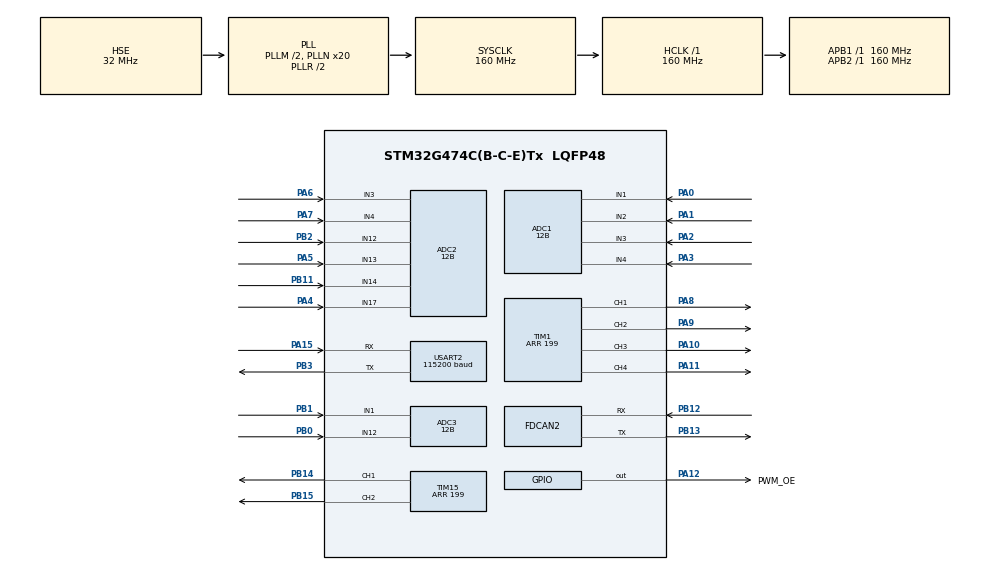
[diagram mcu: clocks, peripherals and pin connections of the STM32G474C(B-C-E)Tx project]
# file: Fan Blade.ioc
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ADC1.Channel-0\#ChannelRegularConversion=ADC_CHANNEL_1
ADC1.Channel-1\#ChannelRegularConversion=ADC_CHANNEL_2
ADC1.Channel-2\#ChannelRegularConversion=ADC_CHANNEL_3
ADC1.Channel-3\#ChannelRegularConversion=ADC_CHANNEL_4
ADC1.ClockPrescaler=ADC_CLOCK_SYNC_PCLK_DIV4
ADC1.ContinuousConvMode=DISABLE
ADC1.DMAContinuousRequests=ENABLE
ADC1.DataAlign=ADC_DATAALIGN_RIGHT
ADC1.DiscontinuousConvMode=DISABLE
ADC1.EOCSelection=ADC_EOC_SEQ_CONV
ADC1.ExternalTrigConv=ADC_EXTERNALTRIG_T6_TRGO
ADC1.ExternalTrigConvEdge=ADC_EXTERNALTRIGCONVEDGE_RISING
ADC1.LowPowerAutoWait=DISABLE
ADC1.NbrOfConversion=4
ADC1.NbrOfConversionFlag=1
ADC1.OffsetNumber-0\#ChannelRegularConversion=ADC_OFFSET_NONE
ADC1.OffsetNumber-1\#ChannelRegularConversion=ADC_OFFSET_NONE
ADC1.OffsetNumber-2\#ChannelRegularConversion=ADC_OFFSET_NONE
ADC1.OffsetNumber-3\#ChannelRegularConversion=ADC_OFFSET_NONE
ADC1.Overrun=ADC_OVR_DATA_OVERWRITTEN
ADC1.OversamplingMode=DISABLE
ADC1.Rank-0\#ChannelRegularConversion=1
ADC1.Rank-1\#ChannelRegularConversion=2
ADC1.Rank-2\#ChannelRegularConversion=3
ADC1.Rank-3\#ChannelRegularConversion=4
ADC1.Resolution=ADC_RESOLUTION_12B
ADC1.SamplingTime-0\#ChannelRegularConversion=ADC_SAMPLETIME_47CYCLES_5
ADC1.SamplingTime-1\#ChannelRegularConversion=ADC_SAMPLETIME_47CYCLES_5
ADC1.SamplingTime-2\#ChannelRegularConversion=ADC_SAMPLETIME_47CYCLES_5
ADC1.SamplingTime-3\#ChannelRegularConversion=ADC_SAMPLETIME_47CYCLES_5
ADC1.ScanConvMode=ADC_SCAN_ENABLE
ADC1.master=1
ADC2.Channel-0\#ChannelRegularConversion=ADC_CHANNEL_17
ADC2.Channel-1\#ChannelRegularConversion=ADC_CHANNEL_13
ADC2.Channel-2\#ChannelRegularConversion=ADC_CHANNEL_3
ADC2.Channel-3\#ChannelRegularConversion=ADC_CHANNEL_4
ADC2.ClockPrescaler=ADC_CLOCK_SYNC_PCLK_DIV4
ADC2.ContinuousConvMode=DISABLE
ADC2.DMAContinuousRequests=ENABLE
ADC2.DataAlign=ADC_DATAALIGN_RIGHT
ADC2.DiscontinuousConvMode=DISABLE
ADC2.EOCSelection=ADC_EOC_SEQ_CONV
ADC2.ExternalTrigConv=ADC_EXTERNALTRIG_T6_TRGO
ADC2.ExternalTrigConvEdge=ADC_EXTERNALTRIGCONVEDGE_RISING
ADC2.LowPowerAutoWait=DISABLE
ADC2.NbrOfConversion=4
ADC2.NbrOfConversionFlag=1
ADC2.OffsetNumber-0\#ChannelRegularConversion=ADC_OFFSET_NONE
ADC2.OffsetNumber-1\#ChannelRegularConversion=ADC_OFFSET_NONE
ADC2.OffsetNumber-2\#ChannelRegularConversion=ADC_OFFSET_NONE
ADC2.OffsetNumber-3\#ChannelRegularConversion=ADC_OFFSET_NONE
ADC2.Overrun=ADC_OVR_DATA_OVERWRITTEN
ADC2.OversamplingMode=DISABLE
ADC2.Rank-0\#ChannelRegularConversion=1
ADC2.Rank-1\#ChannelRegularConversion=2
ADC2.Rank-2\#ChannelRegularConversion=3
ADC2.Rank-3\#ChannelRegularConversion=4
ADC2.Resolution=ADC_RESOLUTION_12B
ADC2.SamplingTime-0\#ChannelRegularConversion=ADC_SAMPLETIME_47CYCLES_5
ADC2.SamplingTime-1\#ChannelRegularConversion=ADC_SAMPLETIME_47CYCLES_5
ADC2.SamplingTime-2\#ChannelRegularConversion=ADC_SAMPLETIME_47CYCLES_5
ADC2.SamplingTime-3\#ChannelRegularConversion=ADC_SAMPLETIME_47CYCLES_5
ADC2.ScanConvMode=ADC_SCAN_ENABLE
ADC3.Channel-0\#ChannelRegularConversion=ADC_CHANNEL_12
ADC3.Channel-1\#ChannelRegularConversion=ADC_CHANNEL_1
ADC3.ClockPrescaler=ADC_CLOCK_SYNC_PCLK_DIV4
ADC3.ContinuousConvMode=DISABLE
ADC3.DMAContinuousRequests=ENABLE
ADC3.DataAlign=ADC_DATAALIGN_RIGHT
ADC3.DiscontinuousConvMode=DISABLE
ADC3.EOCSelection=ADC_EOC_SEQ_CONV
ADC3.ExternalTrigConv=ADC_EXTERNALTRIG_T6_TRGO
ADC3.ExternalTrigConvEdge=ADC_EXTERNALTRIGCONVEDGE_RISING
ADC3.LowPowerAutoWait=DISABLE
ADC3.NbrOfConversion=2
ADC3.NbrOfConversionFlag=1
ADC3.OffsetNumber-0\#ChannelRegularConversion=ADC_OFFSET_NONE
ADC3.OffsetNumber-1\#ChannelRegularConversion=ADC_OFFSET_NONE
ADC3.Overrun=ADC_OVR_DATA_OVERWRITTEN
ADC3.OversamplingMode=DISABLE
ADC3.Rank-0\#ChannelRegularConversion=1
ADC3.Rank-1\#ChannelRegularConversion=2
ADC3.Resolution=ADC_RESOLUTION_12B
ADC3.SamplingTime-0\#ChannelRegularConversion=ADC_SAMPLETIME_47CYCLES_5
ADC3.SamplingTime-1\#ChannelRegularConversion=ADC_SAMPLETIME_47CYCLES_5
ADC3.ScanConvMode=ADC_SCAN_ENABLE
ADC3.master=1
Dma.ADC1.0.Direction=DMA_PERIPH_TO_MEMORY
Dma.ADC1.0.EventEnable=DISABLE
Dma.ADC1.0.Instance=DMA1_Channel1
Dma.ADC1.0.MemDataAlignment=DMA_MDATAALIGN_HALFWORD
Dma.ADC1.0.MemInc=DMA_MINC_ENABLE
Dma.ADC1.0.Mode=DMA_CIRCULAR
Dma.ADC1.0.PeriphDataAlignment=DMA_PDATAALIGN_HALFWORD
Dma.ADC1.0.PeriphInc=DMA_PINC_DISABLE
Dma.ADC1.0.Polarity=HAL_DMAMUX_REQ_GEN_RISING
Dma.ADC1.0.Priority=DMA_PRIORITY_HIGH
Dma.ADC1.0.RequestNumber=1
Dma.ADC1.0.SignalID=NONE
Dma.ADC1.0.SyncEnable=DISABLE
Dma.ADC1.0.SyncPolarity=HAL_DMAMUX_SYNC_NO_EVENT
Dma.ADC1.0.SyncRequestNumber=1
Dma.ADC1.0.SyncSignalID=NONE
Dma.ADC2.1.Direction=DMA_PERIPH_TO_MEMORY
Dma.ADC2.1.EventEnable=DISABLE
Dma.ADC2.1.Instance=DMA1_Channel2
Dma.ADC2.1.MemDataAlignment=DMA_MDATAALIGN_HALFWORD
Dma.ADC2.1.MemInc=DMA_MINC_ENABLE
Dma.ADC2.1.Mode=DMA_CIRCULAR
Dma.ADC2.1.PeriphDataAlignment=DMA_PDATAALIGN_HALFWORD
Dma.ADC2.1.PeriphInc=DMA_PINC_DISABLE
Dma.ADC2.1.Polarity=HAL_DMAMUX_REQ_GEN_RISING
Dma.ADC2.1.Priority=DMA_PRIORITY_HIGH
Dma.ADC2.1.RequestNumber=1
Dma.ADC2.1.SignalID=NONE
Dma.ADC2.1.SyncEnable=DISABLE
Dma.ADC2.1.SyncPolarity=HAL_DMAMUX_SYNC_NO_EVENT
Dma.ADC2.1.SyncRequestNumber=1
Dma.ADC2.1.SyncSignalID=NONE
Dma.ADC3.2.Direction=DMA_PERIPH_TO_MEMORY
Dma.ADC3.2.EventEnable=DISABLE
Dma.ADC3.2.Instance=DMA1_Channel3
Dma.ADC3.2.MemDataAlignment=DMA_MDATAALIGN_HALFWORD
Dma.ADC3.2.MemInc=DMA_MINC_ENABLE
Dma.ADC3.2.Mode=DMA_CIRCULAR
Dma.ADC3.2.PeriphDataAlignment=DMA_PDATAALIGN_HALFWORD
Dma.ADC3.2.PeriphInc=DMA_PINC_DISABLE
Dma.ADC3.2.Polarity=HAL_DMAMUX_REQ_GEN_RISING
Dma.ADC3.2.Priority=DMA_PRIORITY_HIGH
Dma.ADC3.2.RequestNumber=1
Dma.ADC3.2.SignalID=NONE
Dma.ADC3.2.SyncEnable=DISABLE
Dma.ADC3.2.SyncPolarity=HAL_DMAMUX_SYNC_NO_EVENT
Dma.ADC3.2.SyncRequestNumber=1
Dma.ADC3.2.SyncSignalID=NONE
Dma.Request0=ADC1
Dma.Request1=ADC2
Dma.Request2=ADC3
Dma.Request3=USART2_RX
Dma.Request4=USART2_TX
Dma.USART2_RX.3.Direction=DMA_PERIPH_TO_MEMORY
Dma.USART2_RX.3.EventEnable=DISABLE
Dma.USART2_RX.3.Instance=DMA1_Channel4
Dma.USART2_RX.3.MemDataAlignment=DMA_MDATAALIGN_BYTE
Dma.USART2_RX.3.MemInc=DMA_MINC_ENABLE
Dma.USART2_RX.3.Mode=DMA_CIRCULAR
Dma.USART2_RX.3.PeriphDataAlignment=DMA_PDATAALIGN_BYTE
Dma.USART2_RX.3.PeriphInc=DMA_PINC_DISABLE
Dma.USART2_RX.3.Polarity=HAL_DMAMUX_REQ_GEN_RISING
Dma.USART2_RX.3.Priority=DMA_PRIORITY_LOW
Dma.USART2_RX.3.RequestNumber=1
Dma.USART2_RX.3.SignalID=NONE
Dma.USART2_RX.3.SyncEnable=DISABLE
Dma.USART2_RX.3.SyncPolarity=HAL_DMAMUX_SYNC_NO_EVENT
Dma.USART2_RX.3.SyncRequestNumber=1
Dma.USART2_RX.3.SyncSignalID=NONE
Dma.USART2_TX.4.Direction=DMA_MEMORY_TO_PERIPH
Dma.USART2_TX.4.EventEnable=DISABLE
Dma.USART2_TX.4.Instance=DMA1_Channel5
Dma.USART2_TX.4.MemDataAlignment=DMA_MDATAALIGN_BYTE
Dma.USART2_TX.4.MemInc=DMA_MINC_ENABLE
Dma.USART2_TX.4.Mode=DMA_NORMAL
Dma.USART2_TX.4.PeriphDataAlignment=DMA_PDATAALIGN_BYTE
Dma.USART2_TX.4.PeriphInc=DMA_PINC_DISABLE
Dma.USART2_TX.4.Polarity=HAL_DMAMUX_REQ_GEN_RISING
Dma.USART2_TX.4.Priority=DMA_PRIORITY_LOW
Dma.USART2_TX.4.RequestNumber=1
Dma.USART2_TX.4.SignalID=NONE
Dma.USART2_TX.4.SyncEnable=DISABLE
Dma.USART2_TX.4.SyncPolarity=HAL_DMAMUX_SYNC_NO_EVENT
Dma.USART2_TX.4.SyncRequestNumber=1
Dma.USART2_TX.4.SyncSignalID=NONE
FDCAN2.AutoRetransmission=ENABLE
FDCAN2.CalculateBaudRateData=1000000
FDCAN2.CalculateBaudRateNominal=1000000
FDCAN2.CalculateTimeBitData=1000
FDCAN2.CalculateTimeBitNominal=1000
FDCAN2.CalculateTimeQuantumData=50.0
FDCAN2.CalculateTimeQuantumNominal=50.0
FDCAN2.ClockDivider=FDCAN_CLOCK_DIV1
FDCAN2.DataPrescaler=2
FDCAN2.DataSyncJumpWidth=4
FDCAN2.DataTimeSeg1=15
FDCAN2.DataTimeSeg2=4
FDCAN2.ExtFiltersNbr=0
FDCAN2.FrameFormat=FDCAN_FRAME_CLASSIC
FDCAN2.Mode=FDCAN_MODE_NORMAL
FDCAN2.NominalPrescaler=2
FDCAN2.NominalSyncJumpWidth=4
FDCAN2.NominalTimeSeg1=15
FDCAN2.NominalTimeSeg2=4
FDCAN2.ProtocolException=DISABLE
FDCAN2.StdFiltersNbr=2
FDCAN2.TransmitPause=DISABLE
FDCAN2.TxFifoQueueMode=FDCAN_TX_QUEUE_OPERATION
Mcu.Family=STM32G4
Mcu.Name=STM32G474C(B-C-E)Tx
Mcu.Package=LQFP48
NVIC.ADC1_2_IRQn=true\:2\:0\:true\:false\:true\:false\:true\:true
NVIC.ADC3_IRQn=true\:2\:0\:true\:false\:true\:false\:true\:true
NVIC.DMA1_Channel1_IRQn=true\:2\:0\:true\:false\:true\:false\:true\:true
NVIC.DMA1_Channel2_IRQn=true\:2\:0\:true\:false\:true\:false\:true\:true
NVIC.DMA1_Channel3_IRQn=true\:2\:0\:true\:false\:true\:false\:true\:true
NVIC.DMA1_Channel4_IRQn=true\:5\:0\:true\:false\:true\:false\:true\:true
NVIC.DMA1_Channel5_IRQn=true\:5\:0\:true\:false\:true\:false\:true\:true
NVIC.FDCAN2_IT0_IRQn=true\:3\:0\:true\:false\:true\:false\:true\:true
NVIC.PriorityGroup=NVIC_PRIORITYGROUP_4
NVIC.USART2_IRQn=true\:5\:0\:true\:false\:true\:false\:true\:true
PA0.Mode=IN1-Single-Ended
PA0.Signal=ADC1_IN1
PA1.Mode=IN2-Single-Ended
PA1.Signal=ADC1_IN2
PA10.Signal=S_TIM1_CH3
PA11.Signal=S_TIM1_CH4
PA12.GPIO_Label=PWM_OE
PA12.GPIO_ModeDefaultOutputPP=GPIO_MODE_OUTPUT_PP
PA12.GPIO_PuPd=GPIO_NOPULL
PA12.GPIO_Speed=GPIO_SPEED_FREQ_LOW
PA12.PinState=GPIO_PIN_RESET
PA12.Signal=GPIO_Output
PA13.Mode=Serial_Wire
PA13.Signal=SYS_JTMS-SWDIO
PA14.Mode=Serial_Wire
PA14.Signal=SYS_JTCK-SWCLK
PA15.Mode=Asynchronous
PA15.Signal=USART2_RX
PA2.Mode=IN3-Single-Ended
PA2.Signal=ADC1_IN3
PA3.Mode=IN4-Single-Ended
PA3.Signal=ADC1_IN4
PA4.Mode=IN17-Single-Ended
PA4.Signal=ADC2_IN17
PA5.Mode=IN13-Single-Ended
PA5.Signal=ADC2_IN13
PA6.Mode=IN3-Single-Ended
PA6.Signal=ADC2_IN3
PA7.Mode=IN4-Single-Ended
PA7.Signal=ADC2_IN4
PA8.GPIO_PuPd=GPIO_PULLDOWN
PA8.GPIO_Speed=GPIO_SPEED_FREQ_HIGH
PA8.Signal=S_TIM1_CH1
PA9.Signal=S_TIM1_CH2
PB0.Mode=IN12-Single-Ended
PB0.Signal=ADC3_IN12
PB1.Mode=IN1-Single-Ended
PB1.Signal=ADC3_IN1
PB11.Mode=IN14-Single-Ended
PB11.Signal=ADC2_IN14
PB12.Mode=FDCAN_Activate
PB12.Signal=FDCAN2_RX
PB13.Mode=FDCAN_Activate
PB13.Signal=FDCAN2_TX
PB14.Signal=S_TIM15_CH1
PB15.Signal=S_TIM15_CH2
PB2.Mode=IN12-Single-Ended
PB2.Signal=ADC2_IN12
PB3.Mode=Asynchronous
PB3.Signal=USART2_TX
PF0-OSC_IN.Mode=HSE-External-Oscillator
PF0-OSC_IN.Signal=RCC_OSC_IN
PF1-OSC_OUT.Mode=HSE-External-Oscillator
PF1-OSC_OUT.Signal=RCC_OSC_OUT
ProjectManager.HeapSize=0x200
ProjectManager.StackSize=0x1000
ProjectManager.TargetToolchain=CMake
RCC.ADC12CLockSelection=RCC_ADC12CLKSOURCE_SYSCLK
RCC.ADC12Freq_Value=160000000
RCC.ADC345CLockSelection=RCC_ADC345CLKSOURCE_SYSCLK
RCC.ADC345Freq_Value=160000000
RCC.AHBFreq_Value=160000000
RCC.APB1Freq_Value=160000000
RCC.APB1TimFreq_Value=160000000
RCC.APB2Freq_Value=160000000
RCC.APB2TimFreq_Value=160000000
RCC.CK48CLockSelection=RCC_USBCLKSOURCE_HSI48
RCC.CortexFreq_Value=160000000
RCC.EXTERNAL_CLOCK_VALUE=12288000
RCC.FDCANCLockSelection=RCC_FDCANCLKSOURCE_PLL
RCC.HCLKFreq_Value=160000000
RCC.HSE_VALUE=32000000
RCC.HSI48_VALUE=48000000
RCC.HSI_VALUE=16000000
RCC.LSE_VALUE=32768
RCC.PLLM=RCC_PLLM_DIV2
RCC.PLLN=20
RCC.PLLP=RCC_PLLP_DIV2
RCC.PLLQ=RCC_PLLQ_DIV8
RCC.PLLR=RCC_PLLR_DIV2
RCC.PLLSourceVirtual=RCC_PLLSOURCE_HSE
RCC.PWR_Regulator_Voltage_Scale=PWR_REGULATOR_VOLTAGE_SCALE1_BOOST
RCC.SYSCLKFreq_VALUE=160000000
RCC.SYSCLKSource=RCC_SYSCLKSOURCE_PLLCLK
RCC.USART1CLockSelection=RCC_USART1CLKSOURCE_PCLK2
RCC.USART2CLockSelection=RCC_USART2CLKSOURCE_PCLK1
RCC.USBFreq_Value=48000000
RCC.VCOOutputFreq_Value=320000000
SH.S_TIM15_CH1.0=TIM15_CH1,PWM Generation1 CH1
SH.S_TIM15_CH2.0=TIM15_CH2,PWM Generation2 CH2
SH.S_TIM1_CH1.0=TIM1_CH1,PWM Generation1 CH1
SH.S_TIM1_CH2.0=TIM1_CH2,PWM Generation2 CH2
SH.S_TIM1_CH3.0=TIM1_CH3,PWM Generation3 CH3
SH.S_TIM1_CH4.0=TIM1_CH4,PWM Generation4 CH4
TIM1.Channel-PWM\ Generation1\ CH1=TIM_CHANNEL_1
TIM1.Channel-PWM\ Generation2\ CH2=TIM_CHANNEL_2
TIM1.Channel-PWM\ Generation3\ CH3=TIM_CHANNEL_3
TIM1.Channel-PWM\ Generation4\ CH4=TIM_CHANNEL_4
TIM1.PeriodNoDither=199
TIM15.Channel-PWM\ Generation1\ CH1=TIM_CHANNEL_1
TIM15.Channel-PWM\ Generation2\ CH2=TIM_CHANNEL_2
TIM15.PeriodNoDither=199
TIM6.PeriodNoDither=99
TIM6.Prescaler=159
TIM6.TIM_MasterOutputTrigger=TIM_TRGO_UPDATE
USART2.BaudRate=115200
USART2.ClockPrescaler=PRESCALER_DIV1
USART2.FIFOMode=FIFOMODE_DISABLE
USART2.Mode=MODE_TX_RX
USART2.OverSampling=UART_OVERSAMPLING_16
USART2.Parity=PARITY_NONE
USART2.StopBits=STOPBITS_1
USART2.VirtualMode-Asynchronous=VM_ASYNC
USART2.WordLength=WORDLENGTH_8B
VP_SYS_VS_DBSignals.Mode=DisableDeadBatterySignals
VP_TIM15_VS_ClockSourceINT.Mode=Internal
VP_TIM1_VS_ClockSourceINT.Mode=Internal
VP_TIM6_VS_ClockSourceINT.Mode=Enable_Timer
board=custom

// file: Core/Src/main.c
/* USER CODE BEGIN Header */
/**
  ******************************************************************************
  * @file           : main.c
  * @brief          : Main program body
  ******************************************************************************
  * @attention
  *
  * Copyright (c) 2026 STMicroelectronics.
  * All rights reserved.
  *
  * This software is licensed under terms that can be found in the LICENSE file
  * in the root directory of this software component.
  * If no LICENSE file comes with this software, it is provided AS-IS.
  *
  ******************************************************************************
  */
/* USER CODE END Header */
#include "main.h"
#include "adc.h"
#include "dma.h"
#include "fdcan.h"
#include "tim.h"
#include "usart.h"
#include "gpio.h"

/* USER CODE BEGIN Includes */
#include "board_app.h"

/* USER CODE END Includes */

void SystemClock_Config(void);

int main(void)
{

  /* MCU Configuration--------------------------------------------------------*/

  /* Reset of all peripherals, Initializes the Flash interface and the Systick. */
  HAL_Init();

  /* Configure the system clock */
  SystemClock_Config();

  /* Initialize all configured peripherals */
  MX_GPIO_Init();
  MX_DMA_Init();
  MX_ADC1_Init();
  MX_ADC2_Init();
  MX_ADC3_Init();
  MX_FDCAN2_Init();
  MX_USART2_UART_Init();
  MX_TIM1_Init();
  MX_TIM15_Init();
  MX_TIM6_Init();
  /* USER CODE BEGIN 2 */
  BoardApp_Init();

  /* USER CODE END 2 */

  /* Infinite loop */
  while (1)
  {

    /* USER CODE BEGIN 3 */
    BoardApp_Process();
  }
  /* USER CODE END 3 */
}

void SystemClock_Config(void)
{
  RCC_OscInitTypeDef RCC_OscInitStruct = {0};
  RCC_ClkInitTypeDef RCC_ClkInitStruct = {0};

  /** Configure the main internal regulator output voltage
  */
  HAL_PWREx_ControlVoltageScaling(PWR_REGULATOR_VOLTAGE_SCALE1_BOOST);

  /** Initializes the RCC Oscillators according to the specified parameters
  * in the RCC_OscInitTypeDef structure.
  */
  RCC_OscInitStruct.OscillatorType = RCC_OSCILLATORTYPE_HSE;
  RCC_OscInitStruct.HSEState = RCC_HSE_ON;
  RCC_OscInitStruct.PLL.PLLState = RCC_PLL_ON;
  RCC_OscInitStruct.PLL.PLLSource = RCC_PLLSOURCE_HSE;
  RCC_OscInitStruct.PLL.PLLM = RCC_PLLM_DIV2;
  RCC_OscInitStruct.PLL.PLLN = 20;
  RCC_OscInitStruct.PLL.PLLP = RCC_PLLP_DIV2;
  RCC_OscInitStruct.PLL.PLLQ = RCC_PLLQ_DIV8;
  RCC_OscInitStruct.PLL.PLLR = RCC_PLLR_DIV2;
  if (HAL_RCC_OscConfig(&RCC_OscInitStruct) != HAL_OK)
  {
    Error_Handler();
  }

  /** Initializes the CPU, AHB and APB buses clocks
  */
  RCC_ClkInitStruct.ClockType = RCC_CLOCKTYPE_HCLK|RCC_CLOCKTYPE_SYSCLK
                              |RCC_CLOCKTYPE_PCLK1|RCC_CLOCKTYPE_PCLK2;
  RCC_ClkInitStruct.SYSCLKSource = RCC_SYSCLKSOURCE_PLLCLK;
  RCC_ClkInitStruct.AHBCLKDivider = RCC_SYSCLK_DIV1;
  RCC_ClkInitStruct.APB1CLKDivider = RCC_HCLK_DIV1;
  RCC_ClkInitStruct.APB2CLKDivider = RCC_HCLK_DIV1;

  if (HAL_RCC_ClockConfig(&RCC_ClkInitStruct, FLASH_LATENCY_4) != HAL_OK)
  {
    Error_Handler();
  }
}

void Error_Handler(void)
{
  __disable_irq();
  while (1)
  {
  }
}
